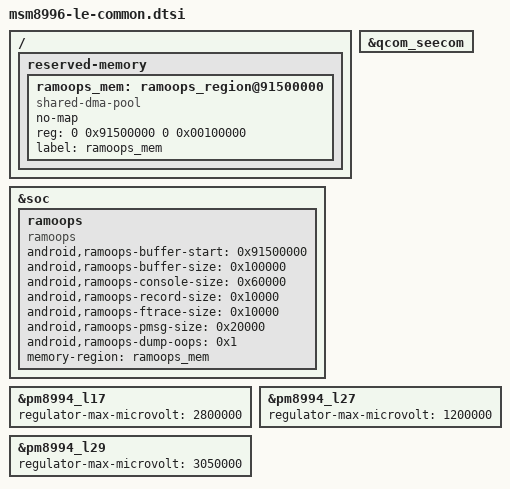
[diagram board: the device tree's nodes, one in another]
/* Copyright (c) 2017, The Linux Foundation. All rights reserved.
 *
 * This program is free software; you can redistribute it and/or modify
 * it under the terms of the GNU General Public License version 2 and
 * only version 2 as published by the Free Software Foundation.
 *
 * This program is distributed in the hope that it will be useful,
 * but WITHOUT ANY WARRANTY; without even the implied warranty of
 * MERCHANTABILITY or FITNESS FOR A PARTICULAR PURPOSE.  See the
 * GNU General Public License for more details.
 */

/delete-node/ &pstore_reserve_mem;

/ {
	reserved-memory {
		ramoops_mem: ramoops_region@91500000 {
			compatible = "shared-dma-pool";
			no-map;
			reg = <0 0x91500000 0 0x00100000>;
			label = "ramoops_mem";
		};
	};
};

&soc {
	ramoops {
		compatible = "ramoops";
		status = "ok";
		android,ramoops-buffer-start = <0x91500000>;
		android,ramoops-buffer-size =  <0x100000>;
		android,ramoops-console-size = <0x60000>;
		android,ramoops-record-size = <0x10000>;
		android,ramoops-ftrace-size = <0x10000>;
		android,ramoops-pmsg-size = <0x20000>;
		android,ramoops-dump-oops = <0x1>;
		memory-region = <&ramoops_mem>;
	};
};

&qcom_seecom {

	/delete-property/ qcom,qsee-reentrancy-support;

};



&pm8994_l17 {

	/delete-property/ regulator-max-microvolt;

	regulator-max-microvolt = <2800000>;

};



&pm8994_l27 {

	/delete-property/ regulator-max-microvolt;

	regulator-max-microvolt = <1200000>;

};



&pm8994_l29 {

	/delete-property/ regulator-max-microvolt;

	regulator-max-microvolt = <3050000>;

};
